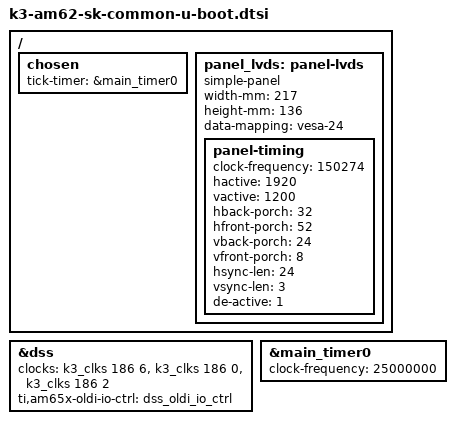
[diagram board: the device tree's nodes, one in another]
// SPDX-License-Identifier: GPL-2.0
/*
 * Common U-Boot dtsi for AM62x SK and derivatives
 * Copyright (C) 2025 Texas Instruments Incorporated - https://www.ti.com/
 */

#include "k3-am625-sk-binman.dtsi"

/ {
	chosen {
		tick-timer = &main_timer0;
	};

	panel_lvds: panel-lvds {
		bootph-pre-ram;
		compatible = "simple-panel";
		status= "okay";
		width-mm = <217>;
		height-mm = <136>;
		data-mapping = "vesa-24";
		panel-timing {
			bootph-pre-ram;
			clock-frequency = <150274>;
			hactive = <1920>;
			vactive = <1200>;
			hback-porch = <32>;
			hfront-porch = <52>;
			vback-porch = <24>;
			vfront-porch = <8>;
			hsync-len = <24>;
			vsync-len = <3>;
			de-active = <1>;
		};
	};
};

&dss {
	clocks = <&k3_clks 186 6>,
		<&k3_clks 186 0>,
		<&k3_clks 186 2>;
	ti,am65x-oldi-io-ctrl = <&dss_oldi_io_ctrl>;
};

&main_timer0 {
	clock-frequency = <25000000>;
};
